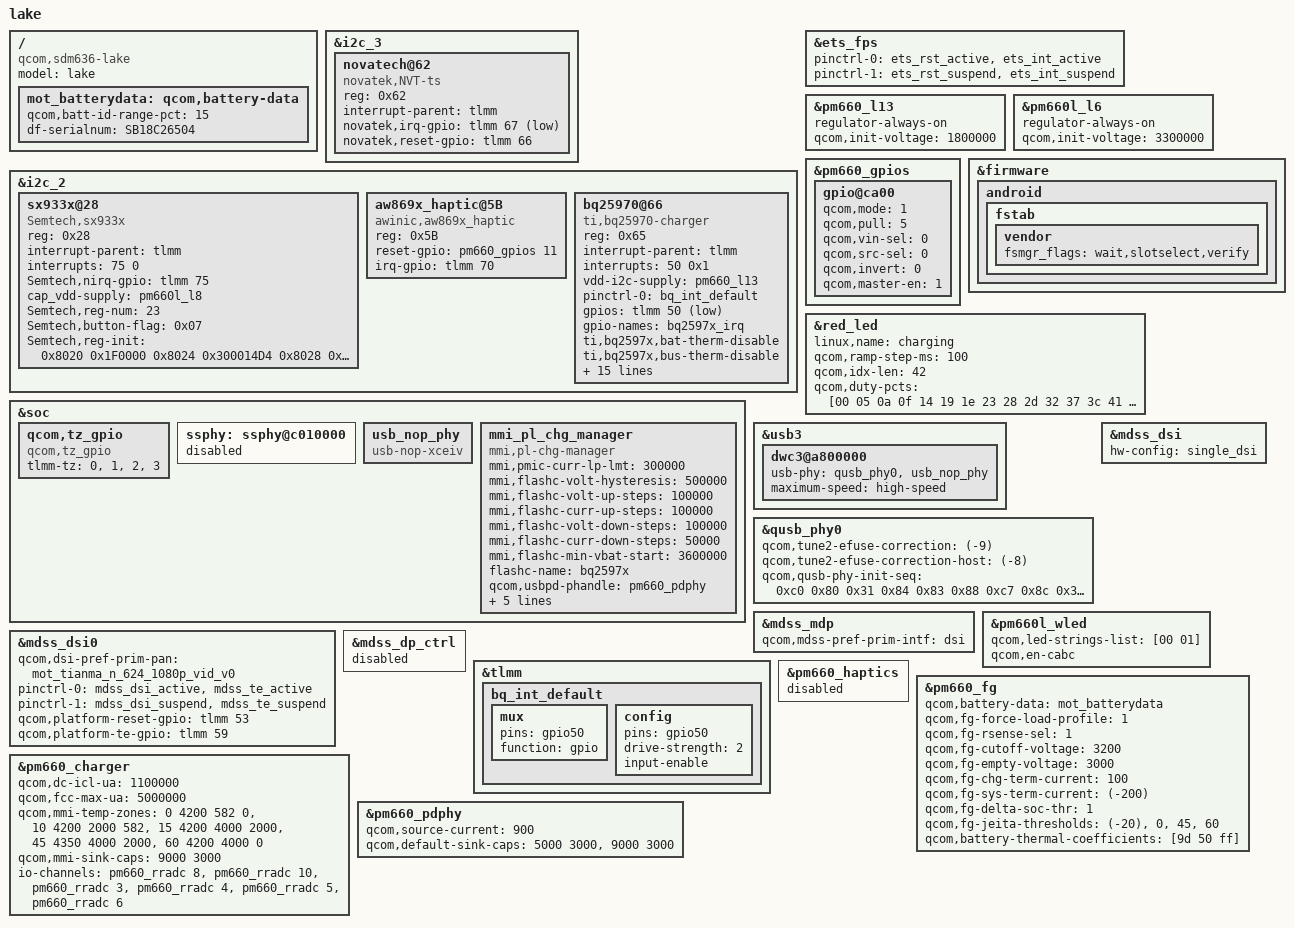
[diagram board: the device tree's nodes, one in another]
/* Copyright (c) 2018, Motorola Mobility Inc. All rights reserved.
 *
 * This program is free software; you can redistribute it and/or modify
 * it under the terms of the GNU General Public License version 2 and
 * only version 2 as published by the Free Software Foundation.
 *
 * This program is distributed in the hope that it will be useful,
 * but WITHOUT ANY WARRANTY; without even the implied warranty of
 * MERCHANTABILITY or FITNESS FOR A PARTICULAR PURPOSE.  See the
 * GNU General Public License for more details.
 */

#include "sdm636-moto-common.dtsi"
#include "dsi-panel-mot-tianma-624-1080p-vid.dtsi"
#include "dsi-panel-mot-tianma-nova-624-1080p-vid.dtsi"
#include "dsi-panel-mot-dummy-qhd-video.dtsi"
#include "sdm636-lake-pinctrl.dtsi"
#include "sdm636-camera-sensor-mot-lake.dtsi"
#include "sdm636-lake-audio.dtsi"
#include "sdm636-egis-fps.dtsi"

#define LAKE_RADIO_NA 1

/ {
	model = "lake";
	compatible = "qcom,sdm636-lake", "qcom,sdm636-moto", "qcom,sdm636";
};

&i2c_3 {
	status = "okay";

	novatech@62 {
		compatible = "novatek,NVT-ts";
		reg = <0x62>;
		interrupt-parent = <&tlmm>;
		novatek,irq-gpio = <&tlmm 67 0x2001>;
		novatek,reset-gpio = <&tlmm 66 0x00>;
	};
};

&i2c_2 {
	status = "okay";
	sx933x@28 {
		compatible = "Semtech,sx933x";
		reg = <0x28>;
		interrupt-parent = <&tlmm>;
		interrupts = <75 0>;
		Semtech,nirq-gpio = <&tlmm 75 0x00>;
		cap_vdd-supply = <&pm660l_l8>;
		Semtech,reg-num = <23>;
		Semtech,button-flag = <0x07>;
		Semtech,reg-init = <0x8020 0x1F0000
			0x8024 0x300014D4 /*again 6.6pf*/
			0x8028 0x24928000
			0x802C 0x300004D4
			0x8030 0x24960000
			0x8034 0x300004D4
			0x8038 0x24B20000
			0x803C 0x300004D4
			0x8040 0x25920000
			0x8044 0x300004D4
			0x8048 0x2C920000
			0x8054 0x03107000 /*ph0*/
			0x8058 0x20600C00
			0x805c 0x0
			0x8064 0x008D0000 /*5mm th*/
			0x8070 0x0
			0x8074 0x03107000 /*ph1*/
			0x8084 0x008D0000 /*5mm th*/
			0x8094 0x03107000 /*ph2*/
			0x80A4 0x008D0000 /*5mm th*/
			0x80B4 0x0010FF00
			0x80D4 0x0010FF00
			0x4004 0x67 >;
	};

	/* AWINIC AW869X Haptic */
	aw869x_haptic@5B {
		compatible = "awinic,aw869x_haptic";
		reg = <0x5B>;
		reset-gpio = <&pm660_gpios 11 0>;
		irq-gpio = <&tlmm 70 0>;
		status = "okay";
	};
	/* AWINIC AW869X Haptic End */
};

&ets_fps {
	/delete-property/ egistec,gpio_ldo1p8_en;
	/delete-property/ egistec,gpio_ldo3p3_en;
	pinctrl-0 = <&ets_rst_active &ets_int_active>;
	pinctrl-1 = <&ets_rst_suspend &ets_int_suspend>;
};

&pm660_l13 {
	regulator-always-on;
	qcom,init-voltage = <1800000>;
};

&pm660l_l6 {
	regulator-always-on;
	qcom,init-voltage = <3300000>;
};

&pm660_gpios {
	/* GPIO 11 for VIB_RST_N */
	gpio@ca00 {
		qcom,mode = <1>;				/* Output */
		qcom,pull = <5>;				/* Pull up */
		qcom,vin-sel = <0>; 			/* VIN1 GPIO_LV */
		qcom,src-sel = <0>; 			/* GPIO */
		qcom,invert = <0>;				/* Invert */
		qcom,master-en = <1>;			/* Enable GPIO */
		status = "okay";
	};
};

&firmware {
	android {
		fstab {
			vendor {
				fsmgr_flags = "wait,slotselect,verify";
			};
		};
	};
};

&red_led {
	linux,name = "charging";
	/delete-property/ linux,default-trigger;
	qcom,ramp-step-ms = <100>;
	qcom,idx-len = <42>;
	qcom,duty-pcts =
		[00 05 0a 0f 14 19 1e 23 28 2d 32 37 3c 41 46 4b 50 55 5a 5f 64
		64 5f 5a 55 50 4b 46 41 3c 37 32 2d 28 23 1e 19 14 0f 0a 05 00];
};

/delete-node/ &green_led;
/delete-node/ &blue_led;

&soc{
/delete-node/ qcom,qbt1000;

	qcom,tz_gpio {
		compatible = "qcom,tz_gpio";
		tlmm-tz = <0>,
			<1>,
			<2>,
			<3>;
	};

	ssphy: ssphy@c010000 {
		status = "disabled";
	};

	usb_nop_phy: usb_nop_phy {
		compatible = "usb-nop-xceiv";
	};

	mmi_pl_chg_manager {
		compatible = "mmi,pl-chg-manager";
		mmi,pmic-curr-lp-lmt = <300000>;
		mmi,flashc-volt-hysteresis = <500000>;
		mmi,flashc-volt-up-steps = <100000>;
		mmi,flashc-curr-up-steps = <100000>;
		mmi,flashc-volt-down-steps = <100000>;
		mmi,flashc-curr-down-steps = <50000>;
		mmi,flashc-min-vbat-start = <3600000>;
		flashc-name = "bq2597x";
		qcom,usbpd-phandle = <&pm660_pdphy>;
		mmi,mmi-pl-temp-zones =
					<0 4200 582 0 0 0 0>,
					<10 4200 2000 4400 582 0 0>,
					<15 4200 4000 4400 2000 0 0>,
					<45 4200 5500 4350 4000 4400 2000>,
					<60 4200 4000 0 0 0 0>;
	};
};

&usb3 {
	dwc3@a800000 {
		usb-phy = <&qusb_phy0>, <&usb_nop_phy>;
		maximum-speed = "high-speed";
	};
};

&qusb_phy0 {
	qcom,tune2-efuse-correction = <(-9)>;
	qcom,tune2-efuse-correction-host = <(-8)>;
	qcom,qusb-phy-init-seq = <0xc0 0x80
				0x31 0x84
				0x83 0x88
				0xc7 0x8c
				0x30 0x08
				0x79 0x0c
				0x21 0x10
				0x14 0x9c
				0x9f 0x1c
				0x00 0x18>;
};

&mdss_mdp {
	qcom,mdss-pref-prim-intf = "dsi";
};

&mdss_dsi {
	hw-config = "single_dsi";
};

&mdss_dsi0 {
	qcom,dsi-pref-prim-pan = <&mot_tianma_n_624_1080p_vid_v0>;
	pinctrl-names = "mdss_default", "mdss_sleep";
	pinctrl-0 = <&mdss_dsi_active &mdss_te_active>;
	pinctrl-1 = <&mdss_dsi_suspend &mdss_te_suspend>;
	qcom,platform-reset-gpio = <&tlmm 53 0>;
	qcom,platform-te-gpio = <&tlmm 59 0>;
};

&pm660l_wled {
	qcom,led-strings-list = [00 01];
	qcom,en-cabc;
};

&mdss_dp_ctrl{
		status = "disabled";
};

&tlmm {
	bq_int_default: bq_int_default {
		mux {
			pins = "gpio50";
			function = "gpio";
		};

		config {
			pins = "gpio50";
			drive-strength = <2>;
			input-enable;
		};
	};
};

&i2c_2 {
	status = "okay";
	bq25970@66 {
		compatible = "ti,bq25970-charger";
		reg = <0x65>;
		interrupt-parent = <&tlmm>;
		interrupts = <50 0x1>;
		vdd-i2c-supply = <&pm660_l13>;
		pinctrl-names = "bq_int_default";
		pinctrl-0 = <&bq_int_default>;
		gpios = <&tlmm 50 0x1>; /* IRQ */
		gpio-names = "bq2597x_irq";

	/*ti,bq2597x,bat-ovp-disable;*/
	/*ti,bq2597x,bat-ovp-alarm-disable;*/
	/*ti,bq2597x,bat-ocp-disable;*/
	/*ti,bq2597x,bat-ocp-alarm-disable;*/
	/*ti,bq2597x,bat-ucp-disable;*/

	/*ti,bq2597x,bus-ovp-alarm-disable;*/
	/*ti,bq2597x,bus-ocp-disable;*/
	/*ti,bq2597x,bus-ocp-alarm-disable;*/

		ti,bq2597x,bat-therm-disable;
		ti,bq2597x,bus-therm-disable;
		ti,bq2597x,die-therm-disable;
		ti,bq2597x,bat-ucp-alarm-disable;

		ti,bq2597x,bat-ovp-threshold = <5050>;
		ti,bq2597x,bat-ovp-alarm-threshold = <5000>;
		ti,bq2597x,bat-ocp-threshold = <8100>;
		ti,bq2597x,bat-ocp-alarm-threshold = <8000>;

		ti,bq2597x,bus-ovp-threshold = <11500>;
		ti,bq2597x,bus-ovp-alarm-threshold = <11000>;
		ti,bq2597x,bus-ocp-threshold = <4250>;
		ti,bq2597x,bus-ocp-alarm-threshold = <4000>;
		ti,bq2597x,bat-ucp-alarm-threshold = <1000>;

		ti,bq2597x,bat-therm-threshold = <0x15>;/*4.1%*/
		ti,bq2597x,bus-therm-threshold = <0x15>;/*4.1%*/
		ti,bq2597x,die-therm-threshold = <125>;

		ti,bq2597x,ac-ovp-threshold = <11>;
	};
};

/{
	mot_batterydata: qcom,battery-data {
		qcom,batt-id-range-pct = <15>;
		df-serialnum = "SB18C26504";

		#include "fg-gen3-batterydata-jx40atl-3010mah.dtsi"
	};
};

&pm660_haptics {
	status = "disabled";
};

&pm660_fg {
	qcom,battery-data = <&mot_batterydata>;
	qcom,fg-force-load-profile = <1>;
	qcom,fg-rsense-sel = <1>;
	qcom,fg-cutoff-voltage = <3200>;
	qcom,fg-empty-voltage = <3000>;
	qcom,fg-chg-term-current = <100>;
	qcom,fg-sys-term-current = <(-200)>;
	qcom,fg-delta-soc-thr = <1>;
	qcom,fg-jeita-thresholds = <(-20)>, <0>, <45>, <60>;
	qcom,battery-thermal-coefficients = [9d 50 ff];
};

&pm660_charger {

	qcom,dc-icl-ua = <1100000>;
	qcom,fcc-max-ua = <5000000>;

	qcom,mmi-temp-zones = <0 4200 582 0>,
				<10 4200 2000 582>,
				<15 4200 4000 2000>,
				<45 4350 4000 2000>,
				<60 4200 4000  0>;
	qcom,mmi-sink-caps = <9000 3000>; /* 9V @ 3A */
	io-channels = <&pm660_rradc 8>,
		      <&pm660_rradc 10>,
		      <&pm660_rradc 3>,
		      <&pm660_rradc 4>,
		      <&pm660_rradc 5>,
		      <&pm660_rradc 6>;
	io-channel-names = "charger_temp",
			   "charger_temp_max",
			   "usbin_i",
			   "usbin_v",
			   "dcin_i",
			   "dcin_v";
};

&pm660_pdphy {
	qcom,source-current = <900>;
	qcom,default-sink-caps = <5000 3000>, /* 5V @ 3A */
				 <9000 3000>; /* 9V @ 3A */
};
